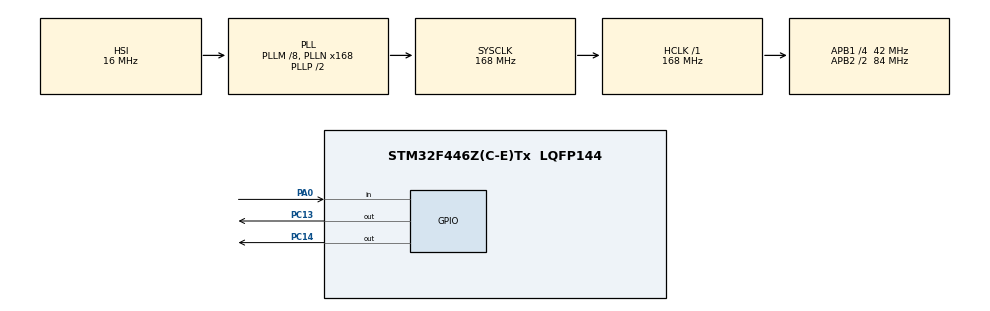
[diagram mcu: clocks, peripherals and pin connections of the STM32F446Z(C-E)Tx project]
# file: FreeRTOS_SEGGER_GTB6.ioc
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FREERTOS.Tasks01=defaultTask,24,128,StartDefaultTask,Default,NULL,Dynamic,NULL,NULL;myTask02,8,128,StartTask02,Default,NULL,Dynamic,NULL,NULL
Mcu.Family=STM32F4
Mcu.Name=STM32F446Z(C-E)Tx
Mcu.Package=LQFP144
NVIC.PriorityGroup=NVIC_PRIORITYGROUP_4
PA0-WKUP.Signal=GPIO_Input
PC13.Signal=GPIO_Output
PC14-OSC32_IN.Signal=GPIO_Output
ProjectManager.HeapSize=0x200
ProjectManager.StackSize=0x400
ProjectManager.TargetToolchain=STM32CubeIDE
RCC.AHBFreq_Value=168000000
RCC.APB1CLKDivider=RCC_HCLK_DIV4
RCC.APB1Freq_Value=42000000
RCC.APB1TimFreq_Value=84000000
RCC.APB2CLKDivider=RCC_HCLK_DIV2
RCC.APB2Freq_Value=84000000
RCC.APB2TimFreq_Value=168000000
RCC.CortexFreq_Value=168000000
RCC.HCLKFreq_Value=168000000
RCC.PLLM=8
RCC.PLLN=168
RCC.SYSCLKFreq_VALUE=168000000
RCC.SYSCLKSource=RCC_SYSCLKSOURCE_PLLCLK
RCC.USBFreq_Value=168000000
RCC.VCOOutputFreq_Value=336000000
VP_FREERTOS_VS_CMSIS_V2.Mode=CMSIS_V2
board=custom

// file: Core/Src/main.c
/* USER CODE BEGIN Header */
/**
  ******************************************************************************
  * @file           : main.c
  * @brief          : Main program body
  ******************************************************************************
  * @attention
  *
  * Copyright (c) 2024 STMicroelectronics.
  * All rights reserved.
  *
  * This software is licensed under terms that can be found in the LICENSE file
  * in the root directory of this software component.
  * If no LICENSE file comes with this software, it is provided AS-IS.
  *
  ******************************************************************************
  */
/* USER CODE END Header */
#include "main.h"
#include "cmsis_os.h"

/* Definitions for defaultTask */
osThreadId_t defaultTaskHandle;
const osThreadAttr_t defaultTask_attributes = {
  .name = "defaultTask",
  .stack_size = 128 * 4,
  .priority = (osPriority_t) osPriorityNormal,
};
/* Definitions for myTask02 */
osThreadId_t myTask02Handle;
const osThreadAttr_t myTask02_attributes = {
  .name = "myTask02",
  .stack_size = 128 * 4,
  .priority = (osPriority_t) osPriorityLow,
};

void SystemClock_Config(void);
static void MX_GPIO_Init(void);
void StartDefaultTask(void *argument);
void StartTask02(void *argument);

int main(void)
{

  /* USER CODE BEGIN 1 */
	DWT->CTRL |= (1 << 0);

  /* USER CODE END 1 */

  /* MCU Configuration--------------------------------------------------------*/

  /* Reset of all peripherals, Initializes the Flash interface and the Systick. */
  HAL_Init();

  /* Configure the system clock */
  SystemClock_Config();

  /* Initialize all configured peripherals */
  MX_GPIO_Init();

  /* Init scheduler */
  osKernelInitialize();

  /* Create the thread(s) */
  /* creation of defaultTask */
  defaultTaskHandle = osThreadNew(StartDefaultTask, NULL, &defaultTask_attributes);

  /* creation of myTask02 */
  myTask02Handle = osThreadNew(StartTask02, NULL, &myTask02_attributes);

  /* Start scheduler */
  osKernelStart();

  /* We should never get here as control is now taken by the scheduler */

  /* Infinite loop */
  while (1)
  {

  }
}

void SystemClock_Config(void)
{
  RCC_OscInitTypeDef RCC_OscInitStruct = {0};
  RCC_ClkInitTypeDef RCC_ClkInitStruct = {0};

  /** Configure the main internal regulator output voltage
  */
  __HAL_RCC_PWR_CLK_ENABLE();
  __HAL_PWR_VOLTAGESCALING_CONFIG(PWR_REGULATOR_VOLTAGE_SCALE1);

  /** Initializes the RCC Oscillators according to the specified parameters
  * in the RCC_OscInitTypeDef structure.
  */
  RCC_OscInitStruct.OscillatorType = RCC_OSCILLATORTYPE_HSI;
  RCC_OscInitStruct.HSIState = RCC_HSI_ON;
  RCC_OscInitStruct.HSICalibrationValue = RCC_HSICALIBRATION_DEFAULT;
  RCC_OscInitStruct.PLL.PLLState = RCC_PLL_ON;
  RCC_OscInitStruct.PLL.PLLSource = RCC_PLLSOURCE_HSI;
  RCC_OscInitStruct.PLL.PLLM = 8;
  RCC_OscInitStruct.PLL.PLLN = 168;
  RCC_OscInitStruct.PLL.PLLP = RCC_PLLP_DIV2;
  RCC_OscInitStruct.PLL.PLLQ = 2;
  RCC_OscInitStruct.PLL.PLLR = 2;
  if (HAL_RCC_OscConfig(&RCC_OscInitStruct) != HAL_OK)
  {
    Error_Handler();
  }

  /** Initializes the CPU, AHB and APB buses clocks
  */
  RCC_ClkInitStruct.ClockType = RCC_CLOCKTYPE_HCLK|RCC_CLOCKTYPE_SYSCLK
                              |RCC_CLOCKTYPE_PCLK1|RCC_CLOCKTYPE_PCLK2;
  RCC_ClkInitStruct.SYSCLKSource = RCC_SYSCLKSOURCE_PLLCLK;
  RCC_ClkInitStruct.AHBCLKDivider = RCC_SYSCLK_DIV1;
  RCC_ClkInitStruct.APB1CLKDivider = RCC_HCLK_DIV4;
  RCC_ClkInitStruct.APB2CLKDivider = RCC_HCLK_DIV2;

  if (HAL_RCC_ClockConfig(&RCC_ClkInitStruct, FLASH_LATENCY_5) != HAL_OK)
  {
    Error_Handler();
  }
}

static void MX_GPIO_Init(void)
{
  GPIO_InitTypeDef GPIO_InitStruct = {0};

  /* GPIO Ports Clock Enable */
  __HAL_RCC_GPIOC_CLK_ENABLE();
  __HAL_RCC_GPIOA_CLK_ENABLE();

  /*Configure GPIO pin Output Level */
  HAL_GPIO_WritePin(GPIOC, GPIO_PIN_13|GPIO_PIN_14, GPIO_PIN_RESET);

  /*Configure GPIO pins : PC13 PC14 */
  GPIO_InitStruct.Pin = GPIO_PIN_13|GPIO_PIN_14;
  GPIO_InitStruct.Mode = GPIO_MODE_OUTPUT_PP;
  GPIO_InitStruct.Pull = GPIO_NOPULL;
  GPIO_InitStruct.Speed = GPIO_SPEED_FREQ_LOW;
  HAL_GPIO_Init(GPIOC, &GPIO_InitStruct);

  /*Configure GPIO pin : PA0 */
  GPIO_InitStruct.Pin = GPIO_PIN_0;
  GPIO_InitStruct.Mode = GPIO_MODE_INPUT;
  GPIO_InitStruct.Pull = GPIO_NOPULL;
  HAL_GPIO_Init(GPIOA, &GPIO_InitStruct);

}

void StartDefaultTask(void *argument)
{
  /* USER CODE BEGIN 5 */
  /* Infinite loop */
  for(;;)
  {
	  if(HAL_GPIO_ReadPin(GPIOA, GPIO_PIN_0))
	  {
		  HAL_GPIO_WritePin(GPIOC, GPIO_PIN_14, GPIO_PIN_SET);
	  }
	  else
	  {
		  HAL_GPIO_WritePin(GPIOC, GPIO_PIN_14, GPIO_PIN_RESET);
	  }
  }
  /* USER CODE END 5 */
}

void StartTask02(void *argument)
{
  for(;;)
  {
    osDelay(1);
  }
}

void Error_Handler(void)
{
  __disable_irq();
  while (1)
  {
  }
}
